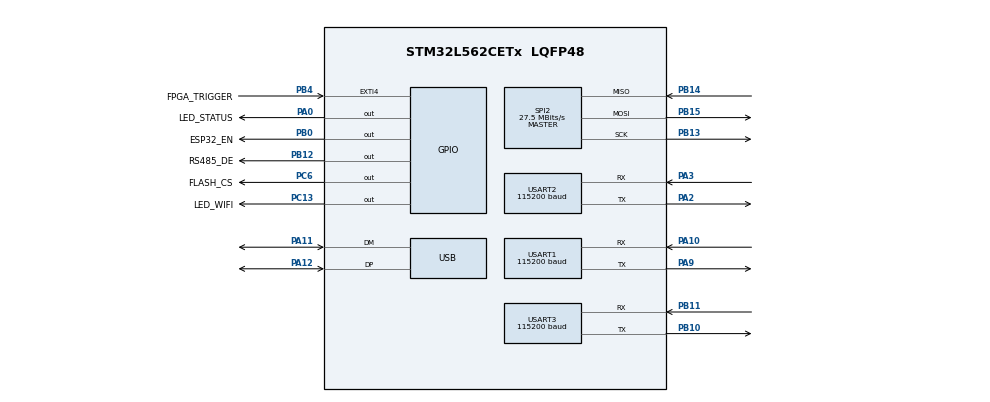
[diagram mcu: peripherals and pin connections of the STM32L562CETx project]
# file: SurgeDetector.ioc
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# SurgeDetector - STM32L562CET6 + FreeRTOS
# NOTE: This .ioc is a best-effort hand-authored reference matching the
# peripheral/FreeRTOS configuration documented in README.md section 3.
# Open it with your installed STM32CubeMX version, verify Pinout/Clock
# Configuration against your actual board, then "Generate Code".
DMA.Request0=USART1_RX
DMA.Request1=USART2_RX
DMA.Request2=USART3_RX
DMA.RequestsNb=3
DMA.USART1_RX.0.Direction=DMA_PERIPH_TO_MEMORY
DMA.USART1_RX.0.EventEnable=false
DMA.USART1_RX.0.Instance=DMA1_Channel1
DMA.USART1_RX.0.MemInc=DMA_MINC_ENABLE
DMA.USART1_RX.0.Mode=DMA_NORMAL
DMA.USART1_RX.0.PeriphInc=DMA_PINC_DISABLE
DMA.USART1_RX.0.Priority=DMA_PRIORITY_MEDIUM
DMA.USART2_RX.1.Direction=DMA_PERIPH_TO_MEMORY
DMA.USART2_RX.1.Instance=DMA1_Channel2
DMA.USART2_RX.1.MemInc=DMA_MINC_ENABLE
DMA.USART2_RX.1.Mode=DMA_NORMAL
DMA.USART2_RX.1.PeriphInc=DMA_PINC_DISABLE
DMA.USART2_RX.1.Priority=DMA_PRIORITY_HIGH
DMA.USART3_RX.2.Direction=DMA_PERIPH_TO_MEMORY
DMA.USART3_RX.2.Instance=DMA1_Channel3
DMA.USART3_RX.2.MemInc=DMA_MINC_ENABLE
DMA.USART3_RX.2.Mode=DMA_NORMAL
DMA.USART3_RX.2.PeriphInc=DMA_PINC_DISABLE
DMA.USART3_RX.2.Priority=DMA_PRIORITY_MEDIUM
FREERTOS.Queues01=qFpgaToWifi,8,SurgeData_t,0,Dynamic,NULL,NULL;qFpgaToPc,8,SurgeData_t,0,Dynamic,NULL,NULL;qWifiCmd,4,WifiCmdMsg_t,0,Dynamic,NULL,NULL
FREERTOS.Tasks01=defaultTask,24,256,StartDefaultTask,Default,NULL,Dynamic,NULL,NULL
FREERTOS.configCHECK_FOR_STACK_OVERFLOW=2
FREERTOS.configMAX_PRIORITIES=56
FREERTOS.configTICK_RATE_HZ=1000
FREERTOS.configTIMER_TASK_PRIORITY=55
FREERTOS.configTOTAL_HEAP_SIZE=20480
FREERTOS.configUSE_TIMERS=1
Mcu.Family=STM32L5
Mcu.Name=STM32L562CETx
Mcu.Package=LQFP48
NVIC.DMA1_Channel1_IRQn=true\:5\:0\:true\:false\:true\:true\:true\:true
NVIC.DMA1_Channel2_IRQn=true\:4\:0\:true\:false\:true\:true\:true\:true
NVIC.DMA1_Channel3_IRQn=true\:5\:0\:true\:false\:true\:true\:true\:true
NVIC.EXTI4_IRQn=true\:5\:0\:true\:false\:true\:true\:true\:true
NVIC.PriorityGroup=NVIC_PRIORITYGROUP_4
NVIC.USART1_IRQn=true\:5\:0\:true\:false\:true\:true\:true\:true
NVIC.USART2_IRQn=true\:4\:0\:true\:false\:true\:true\:true\:true
NVIC.USART3_IRQn=true\:5\:0\:true\:false\:true\:true\:true\:true
NVIC.USB_FS_IRQn=true\:5\:0\:true\:false\:true\:true\:true\:true
PA0.GPIO_Label=LED_STATUS
PA0.Signal=GPIO_Output
PA2.Mode=Asynchronous
PA2.Signal=USART2_TX
PA3.Mode=Asynchronous
PA3.Signal=USART2_RX
PA9.Mode=Asynchronous
PA9.Signal=USART1_TX
PA10.Mode=Asynchronous
PA10.Signal=USART1_RX
PA11.Mode=Device_Only
PA11.Signal=USB_DM
PA12.Mode=Device_Only
PA12.Signal=USB_DP
PA13.Mode=Serial_Wire
PA13.Signal=SYS_JTMS-SWDIO
PA14.Mode=Serial_Wire
PA14.Signal=SYS_JTCK-SWCLK
PB0.GPIO_Label=ESP32_EN
PB0.Signal=GPIO_Output
PB4.GPIO_Label=FPGA_TRIGGER
PB4.GPIO_PuPd=GPIO_PULLUP
PB4.Signal=GPXTI4
PB10.Mode=Asynchronous
PB10.Signal=USART3_TX
PB11.Mode=Asynchronous
PB11.Signal=USART3_RX
PB12.GPIO_Label=RS485_DE
PB12.Signal=GPIO_Output
PB13.Mode=Full_Duplex_Master
PB13.Signal=SPI2_SCK
PB14.Mode=Full_Duplex_Master
PB14.Signal=SPI2_MISO
PB15.Mode=Full_Duplex_Master
PB15.Signal=SPI2_MOSI
PC6.GPIO_Label=FLASH_CS
PC6.Signal=GPIO_Output
PC13.GPIO_Label=LED_WIFI
PC13.Signal=GPIO_Output
ProjectManager.HeapSize=0x400
ProjectManager.StackSize=0x800
ProjectManager.TargetToolchain=STM32CubeIDE
RCC.ADCFreq_Value=110000000
RCC.AHBFreq_Value=110000000
RCC.APB1Freq_Value=110000000
RCC.APB1TimFreq_Value=110000000
RCC.APB2Freq_Value=110000000
RCC.APB2TimFreq_Value=110000000
RCC.HCLKFreq_Value=110000000
RCC.HSI48_VALUE=48000000
RCC.MSIClockRange=RCC_MSIRANGE_11
RCC.SYSCLKFreq_VALUE=110000000
RCC.SYSCLKSource=RCC_SYSCLKSOURCE_PLLCLK
RCC.USBFreq_Value=48000000
RCC.VCOOutputFreq_Value=220000000
SPI2.CalculateBaudRate=27.5 MBits/s
SPI2.DataSize=SPI_DATASIZE_8BIT
SPI2.Direction=SPI_DIRECTION_2LINES
SPI2.Mode=SPI_MODE_MASTER
SPI2.BaudRatePrescaler=SPI_BAUDRATEPRESCALER_4
SPI2.CLKPhase=SPI_PHASE_1EDGE
SPI2.CLKPolarity=SPI_POLARITY_LOW
SPI2.VirtualType=VM_MASTER
USART1.BaudRate=115200
USART1.Parity=UART_PARITY_NONE
USART1.StopBits=UART_STOPBITS_1
USART1.VirtualMode=Asynchronous
USART1.WordLength=UART_WORDLENGTH_8B
USART2.BaudRate=115200
USART2.Parity=UART_PARITY_NONE
USART2.StopBits=UART_STOPBITS_1
USART2.VirtualMode=Asynchronous
USART2.WordLength=UART_WORDLENGTH_8B
USART3.BaudRate=115200
USART3.OverSampling=UART_OVERSAMPLING_16
USART3.DEPolarity=UART_DE_POLARITY_HIGH
USART3.Parity=UART_PARITY_NONE
USART3.StopBits=UART_STOPBITS_1
USART3.VirtualMode=Asynchronous
USART3.WordLength=UART_WORDLENGTH_8B
USB_DEVICE.CLASS_NAME_FS=CDC
USB_DEVICE.VirtualMode=Cdc
USB_DEVICE.VirtualModeFS=Cdc_FS
VP_FREERTOS_VS_CMSIS_V2.Mode=CMSIS_V2
VP_SYS_VS_tim6.Mode=TIM6
board=custom

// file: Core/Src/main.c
/**
 * main.c — CubeMX 표준 구조 요약본.
 * 실제 프로젝트에서는 CubeMX가 생성하는 MX_GPIO_Init/MX_DMA_Init/MX_USARTx_UART_Init/
 * MX_SPI2_Init/MX_USB_Device_Init/SystemClock_Config 전체 구현이 이 파일에 포함됩니다.
 * 여기서는 CubeMX가 만들지 않는 "USER CODE" 삽입 지점만 표시합니다.
 */
#include "main.h"
#include "cmsis_os2.h"

/* CubeMX가 생성 (usart.c/spi.c/usb_device.c/dma.c/gpio.c) */
extern void MX_GPIO_Init(void);
extern void MX_DMA_Init(void);
extern void MX_USART1_UART_Init(void);
extern void MX_USART2_UART_Init(void);
extern void MX_USART3_UART_Init(void);
extern void MX_SPI2_Init(void);
extern void MX_USB_Device_Init(void);
extern void SystemClock_Config(void);

/* Core/Src/app_freertos.c */
extern void MX_FREERTOS_Init(void);

int main(void)
{
    HAL_Init();
    SystemClock_Config();

    MX_GPIO_Init();
    MX_DMA_Init();
    MX_USART1_UART_Init();
    MX_USART2_UART_Init();
    MX_USART3_UART_Init();
    MX_SPI2_Init();
    MX_USB_Device_Init();

    /* USER CODE BEGIN 2 */
    /* App 모듈 자체 RTOS 오브젝트 생성은 MX_FREERTOS_Init() -> StartDefaultTask()
     * 안에서 수행되므로 여기서는 별도 초기화가 필요 없다. */
    /* USER CODE END 2 */

    MX_FREERTOS_Init();

    osKernelStart();

    /* osKernelStart()는 정상 동작 시 반환하지 않는다 */
    for (;;)
    {
    }
}

void Error_Handler(void)
{
    __disable_irq();
    while (1)
    {
    }
}

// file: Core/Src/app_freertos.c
/**
 * app_freertos.c — CubeMX가 생성하는 Core/Src/freertos.c에 해당.
 * MX_FREERTOS_Init()에서 defaultTask만 생성하고, 나머지 모듈(WiFi/FPGA/PcComm)의
 * 태스크/큐/세마포어는 각 모듈의 App_xxx_Init()이 스스로 생성하도록 위임한다
 * (README.md 3.8.1 참조).
 */
#include "cmsis_os2.h"
#include "main.h"
#include "app_config.h"
#include "app_wifi.h"
#include "app_fpga.h"
#include "app_pccomm.h"

static osThreadId_t   defaultTaskHandle;
static osTimerId_t    tmrHeartbeat;
static osTimerId_t    tmrWifiWatchdog;

static void StartDefaultTask(void *argument);
static void Heartbeat_Callback(void *argument);
static void WifiWatchdog_Callback(void *argument);

void MX_FREERTOS_Init(void)
{
    const osThreadAttr_t defaultTask_attributes = {
        .name = "defaultTask",
        .priority = (osPriority_t) osPriorityNormal,
        .stack_size = 256 * 4,
    };
    defaultTaskHandle = osThreadNew(StartDefaultTask, NULL, &defaultTask_attributes);

    const osTimerAttr_t hbAttr = { .name = "tmrHeartbeat" };
    tmrHeartbeat = osTimerNew(Heartbeat_Callback, osTimerPeriodic, NULL, &hbAttr);

    const osTimerAttr_t wdAttr = { .name = "tmrWifiWatchdog" };
    tmrWifiWatchdog = osTimerNew(WifiWatchdog_Callback, osTimerPeriodic, NULL, &wdAttr);
}

static void Heartbeat_Callback(void *argument)
{
    (void)argument;
    HAL_GPIO_TogglePin(LED_STATUS_GPIO_Port, LED_STATUS_Pin);
}

static void WifiWatchdog_Callback(void *argument)
{
    (void)argument;
    uint32_t flags = osEventFlagsGet(egSysStatus);

    HAL_GPIO_WritePin(LED_WIFI_GPIO_Port, LED_WIFI_Pin,
                       (flags & EVT_SERVER_CONNECTED) ? GPIO_PIN_SET : GPIO_PIN_RESET);

    if ((flags & EVT_SERVER_CONNECTED) == 0u)
    {
        WifiCmdMsg_t m = { .id = WIFI_CMD_FORCE_RECONNECT };
        /* wifiTask가 자체 재시도 루프를 돌고 있을 때는 큐가 이미 비어있지 않을 수
         * 있으므로 non-blocking put 실패는 무시(다음 주기에 재시도) */
        osMessageQueuePut(qWifiCmd, &m, 0, 0);
    }
}

/**
 * StartDefaultTask — 시스템 초기화 순서를 보장하는 진입점.
 * 1) 외부 Flash + 설정 로드 (EVT_FLASH_READY, EVT_CONFIG_LOADED 셋)
 * 2) 나머지 모듈 태스크 생성 (모두 EVT_CONFIG_LOADED 대기 후 동작 시작)
 * 3) 하트비트/워치독 타이머 시작
 * 4) 이후 defaultTask는 유휴 루프(추가로 IWDG refresh 등 시스템 감시 용도로 확장 가능)
 */
static void StartDefaultTask(void *argument)
{
    (void)argument;

    App_Config_Init();     /* SPI Flash + mutexFlash + egSysStatus 생성/초기화 */

    App_WiFi_Init();       /* wifiTask, qFpgaToWifi, qWifiCmd, mutexWifiUart, semUart1Event */
    App_FPGA_Init();       /* fpgaTask, semFpgaTrigger, semUart2RxCplt */
    App_PcComm_Init();     /* pcUartTask, pcUsbTask, pcDataPushTask, qFpgaToPc, semUart3Event */

    osTimerStart(tmrHeartbeat, 500);
    osTimerStart(tmrWifiWatchdog, 5000);

    for (;;)
    {
        /* 향후 IWDG_Refresh() 등 시스템 레벨 감시 로직 추가 지점 */
        osDelay(1000);
    }
}
